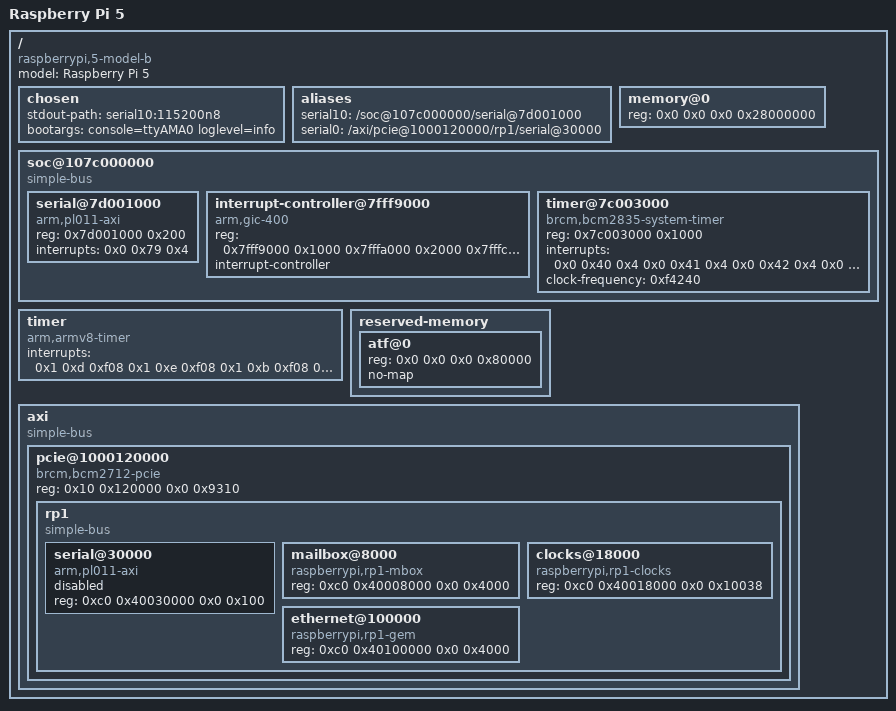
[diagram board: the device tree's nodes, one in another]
// SPDX-License-Identifier: BSD-3-Clause
// Generated by tests/fixtures/pi5/generate.py; values from the official Pi 5 DTB.
/dts-v1/;

/ {
    compatible = "raspberrypi,5-model-b", "brcm,bcm2712";
    model = "Raspberry Pi 5";
    #address-cells = <0x2>;
    #size-cells = <0x2>;
    chosen {
        stdout-path = "serial10:115200n8";
        bootargs = "console=ttyAMA0 loglevel=info";
    };
    aliases {
        serial10 = "/soc@107c000000/serial@7d001000";
        serial0 = "/axi/pcie@1000120000/rp1/serial@30000";
    };
    memory@0 {
        device_type = "memory";
        reg = <0x0 0x0 0x0 0x28000000>;
    };
    soc@107c000000 {
        compatible = "simple-bus";
        #address-cells = <0x1>;
        #size-cells = <0x1>;
        ranges = <0x0 0x10 0x0 0x80000000>;
        serial@7d001000 {
            compatible = "arm,pl011-axi", "arm,pl011", "arm,primecell";
            reg = <0x7d001000 0x200>;
            interrupts = <0x0 0x79 0x4>;
            status = "okay";
        };
        interrupt-controller@7fff9000 {
            compatible = "arm,gic-400";
            reg = <0x7fff9000 0x1000 0x7fffa000 0x2000 0x7fffc000 0x2000 0x7fffe000 0x2000>;
            interrupt-controller;
            #interrupt-cells = <0x3>;
        };
        timer@7c003000 {
            compatible = "brcm,bcm2835-system-timer";
            reg = <0x7c003000 0x1000>;
            interrupts = <0x0 0x40 0x4 0x0 0x41 0x4 0x0 0x42 0x4 0x0 0x43 0x4>;
            clock-frequency = <0xf4240>;
        };
    };
    timer {
        compatible = "arm,armv8-timer";
        interrupts = <0x1 0xd 0xf08 0x1 0xe 0xf08 0x1 0xb 0xf08 0x1 0xa 0xf08>;
    };
    reserved-memory {
        #address-cells = <0x2>;
        #size-cells = <0x2>;
        ranges = <>;
        atf@0 {
            reg = <0x0 0x0 0x0 0x80000>;
            no-map;
        };
    };
    axi {
        compatible = "simple-bus";
        #address-cells = <0x2>;
        #size-cells = <0x2>;
        pcie@1000120000 {
            compatible = "brcm,bcm2712-pcie";
            reg = <0x10 0x120000 0x0 0x9310>;
            device_type = "pci";
            #address-cells = <0x3>;
            #size-cells = <0x2>;
            ranges = <0x2000000 0x0 0x0 0x1f 0x0 0x0 0xfffffffc 0x43000000 0x4 0x0 0x1c 0x0 0x3 0x0>;
            status = "okay";
            rp1 {
                compatible = "simple-bus";
                #address-cells = <0x2>;
                #size-cells = <0x2>;
                ranges = <0xc0 0x40000000 0x2000000 0x0 0x0 0x0 0x410000>;
                serial@30000 {
                    compatible = "arm,pl011-axi", "arm,pl011";
                    reg = <0xc0 0x40030000 0x0 0x100>;
                    status = "disabled";
                };
                mailbox@8000 {
                    compatible = "raspberrypi,rp1-mbox";
                    reg = <0xc0 0x40008000 0x0 0x4000>;
                    status = "okay";
                };
                clocks@18000 {
                    compatible = "raspberrypi,rp1-clocks";
                    reg = <0xc0 0x40018000 0x0 0x10038>;
                };
                ethernet@100000 {
                    compatible = "raspberrypi,rp1-gem";
                    reg = <0xc0 0x40100000 0x0 0x4000>;
                    status = "okay";
                };
            };
        };
    };
};
